# RL6955_IP_SVD register map
Vendor: Realtek
Registers are 32-bit, read-write, reset 0x0 unless marked. A register's access mark holds for its fields unless they carry their own. Offsets are from the block's base; [hi:lo] are bit positions; {n}, {i} and the like mark numbered series.

## WLON
Base 0x40000000
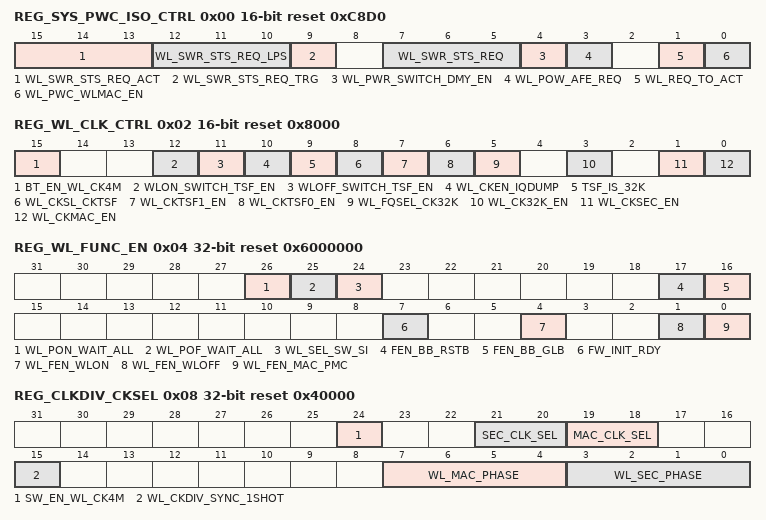
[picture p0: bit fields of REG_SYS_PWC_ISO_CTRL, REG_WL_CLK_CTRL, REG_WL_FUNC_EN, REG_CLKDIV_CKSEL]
0x00 REG_SYS_PWC_ISO_CTRL 16-bit access per field reset 0xC8D0
  [15:13] WL_SWR_STS_REQ_ACT rw — 000: RSVD 001: state1 0.7/PC/PFM 010: state2 0.8/PC/PFM 011: state3 0.9/PC/PFM 100: state4 0.9/SLP/PFM 101: state5 0.9/SLP/PWM 110: state6 0.9/NORM/PWM 111: state7 1.0/NORM/PWM
  [12:10] WL_SWR_STS_REQ_LPS rw — 000: RSVD 001: state1 0.7/PC/PFM 010: state2 0.8/PC/PFM 011: state3 0.9/PC/PFM 100: state4 0.9/SLP/PFM 101: state5 0.9/SLP/PWM 110: state6 0.9/NORM/PWM 111: state7 1.0/NORM/PWM
  [9] WL_SWR_STS_REQ_TRG rw — 1:wl request switch regu status to active mode,which means selectl 0x00[11:9] as request 0:wl request switch regu status to lps mode,which means selectl 0x00[7:5] as request
  [7:5] WL_SWR_STS_REQ ro — the SWR request mode of wifi
  [4] WL_PWR_SWITCH_DMY_EN rw — 1:enable wl dummy load when wlan is switching power mode 0:disable wl dummy load when wlan is switching power mode
  [3] WL_POW_AFE_REQ rw — AFE power on request to afe_ctrl 1:request to turn on AFE pwr 0:turn off AFE pwr
  [1] WL_REQ_TO_ACT rw — notify system to act
  [0] WL_PWC_WLMAC_EN rw — 1: Enable WLOFF power cut
0x02 REG_WL_CLK_CTRL 16-bit access per field reset 0x8000
  [15] BT_EN_WL_CK4M rw — enable WL OSC 4M when bt is active
  [12] WLON_SWITCH_TSF_EN rw — enable wlpmc switch TSF clock to MAC clock
  [11] WLOFF_SWITCH_TSF_EN rw — enable wlpmc switch TSF clock to 32K clock
  [10] WL_CKEN_IQDUMP rw — 0: disable clock for iqdump (LA MODE) 1: enable clock for iqdump (LA MODE) same clock source as security clock
  [9] TSF_IS_32K ro — WL TSF clock status: 0: MAC clock 1: 32K clock
  [8] WL_CKSL_CKTSF rw — 1: TSF clock switch to 32.768KHz; 0: TSF clock switch to MAC clock
  [7] WL_CKTSF1_EN rw — 1: enable port2 tsf clock; 0: gated
  [6] WL_CKTSF0_EN rw — 1: enable port1 tsf clock; 0: gated
  [5] WL_FQSEL_CK32K rw — 1:32K frequency select 32.768KHz 0:32K frequency select 32KHz
  [3] WL_CK32K_EN rw — 1: enable 32k clock; 0: gated
  [1] WL_CKSEC_EN rw — 1: enable MAC security engine clock; 0: gated
  [0] WL_CKMAC_EN rw — 1: enable MAC clock; 0: gated
0x04 REG_WL_FUNC_EN reset 0x6000000
  [26] WL_PON_WAIT_ALL — 1:wait rdy for swr and xtal and pwc in the same state when power on to save time and power
  [25] WL_POF_WAIT_ALL — 1:wait rdy for swr and xtal in the same state when power off to save time and power
  [24] WL_SEL_SW_SI — indicate SW use indirect path to access WLRFC register
  [17] FEN_BB_RSTB — When this bit is set to 0, CCK and OFDM are disabled, and clock are gated. Otherwise, CCK and OFDM are enabled.
  [16] FEN_BB_GLB — When this bit is set to 0 whole BB is reset. When this bit is set, BB is enabled.
  [7] FW_INIT_RDY — CPU fw initialize ready, set by CPU(txrpt info update,used in ptcl)
  [4] WL_FEN_WLON — 1: enable WL partial ON; 0: reset
  [1] WL_FEN_WLOFF — 1: enable WLOFF; 0: reset
  [0] WL_FEN_MAC_PMC — 1: enable MAC PMC; 0: reset
0x08 REG_CLKDIV_CKSEL reset 0x40000
  [24] SW_EN_WL_CK4M — enable WL OSC 4M when cpu want to access wlon reg and wlpmc buffer
  [21:20] SEC_CLK_SEL — 11/10:40M 01:80M 00:160M
  [19:18] MAC_CLK_SEL — 11/10:20M 01:40M 00:80M
  [15] WL_CKDIV_SYNC_1SHOT — 1: sync 40M/80M clock phase with PLL
  [7:4] WL_MAC_PHASE — 40M MAC clock phase control
  [3:0] WL_SEC_PHASE — 80M security clock phase control
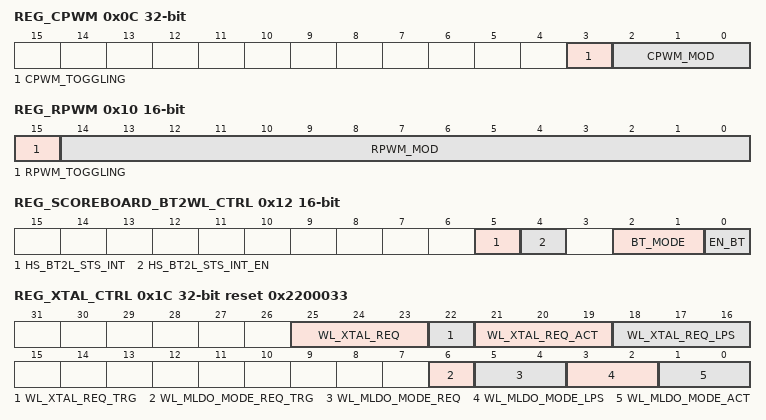
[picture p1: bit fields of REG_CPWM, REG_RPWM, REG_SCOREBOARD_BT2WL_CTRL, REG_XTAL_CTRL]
0x0C REG_CPWM
  [3] CPWM_TOGGLING — Toggling bit : one bit sequence number bit. When this bit is toggled, interrupt is send to HISR.CPWMINT.
  [2:0] CPWM_MOD — The current power mode index.
0x10 REG_RPWM 16-bit
  [15] RPWM_TOGGLING — Toggling bit : one bit sequence number bit. When this bit is toggled, interrupt is send to FISR.RPWMINT.
  [14:0] RPWM_MOD — The current power mode index.
0x12 REG_SCOREBOARD_BT2WL_CTRL 16-bit access per field
  [5] HS_BT2L_STS_INT ro — when bit31 toggles, this interrupt will be assert
  [4] HS_BT2L_STS_INT_EN rw — when bit31 toggles, this interrupt will be assert
  [2:1] BT_MODE rw — Bluetooth Mode
  [0] EN_BT rw — Enable PTA ( from BT side)
0x14 REG_SCOREBOARD_BT2WL ro
  [31:0] RD_BT2WL_INFO — Read Data : WL TO BT INFO, WLON Status Report
0x18 REG_SCOREBOARD_WL2BT
  [31:0] RD_WL2BT_INFO — WLON Status Report TO BTON
0x1C REG_XTAL_CTRL access per field reset 0x2200033
  [25:23] WL_XTAL_REQ ro — the xtal request mode of wifi
  [22] WL_XTAL_REQ_TRG rw — 1: wl request xtal status to active mode,which means selectl 0x30[6:5] as request 0: wl request xtal status to lps mode,which means selectl 0x30[4:3] as request
  [21:19] WL_XTAL_REQ_ACT rw — 000:xtal off 001:xtal lps mode gating 40M 010:xtal lps mode enable 40M 011:xtal normal mode 100:xtal hp mode
  [18:16] WL_XTAL_REQ_LPS rw — 000:xtal off 001:xtal lps mode gating 40M 010:xtal lps mode enable 40M 011:xtal normal mode 100:xtal hp mode
  [6] WL_MLDO_MODE_REQ_TRG rw — Write 1 to trigger switch LDO mode when wifi is active, pulse
  [5:4] WL_MLDO_MODE_REQ ro — The ldo request mode of wifi
  [3:2] WL_MLDO_MODE_LPS rw — 00: analog LDO off 01: analog LDO off sleep 10: analog LDO normal -- dummy load 11: analog LDO normal -- no dummy load
  [1:0] WL_MLDO_MODE_ACT rw — 00: analog LDO off 01: analog LDO off sleep 10: analog LDO normal -- dummy load 11: analog LDO normal -- no dummy load
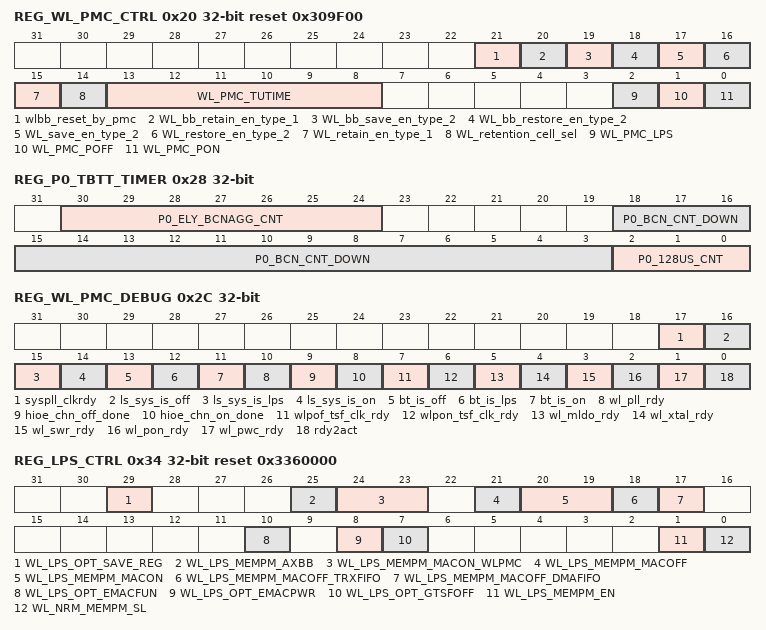
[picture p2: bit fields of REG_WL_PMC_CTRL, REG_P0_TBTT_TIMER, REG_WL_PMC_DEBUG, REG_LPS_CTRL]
0x20 REG_WL_PMC_CTRL access per field reset 0x309F00
  [21] wlbb_reset_by_pmc rw — 1: release wlbb glb reset and restore wlbb retention dff by wlpmc 0:release wlbb glb reset and restore wlbb retention dff by sw or hioe
  [20] WL_bb_retain_en_type_1 rw — 1 to 0:gen req to restore register in power on flow 0 to 1:gen req to backup register in power on flow default should be 1,otherwise there be unexpected leakage power when VCC is power off and VCCG is still on
  [19] WL_bb_save_en_type_2 wo — enable saving value of retention DFF when wlbb power off or pg,should be assert when reset is high
  [18] WL_bb_restore_en_type_2 wo — enable restoring value of retention DFF when wlbb power on,should be assert when reset is high
  [17] WL_save_en_type_2 wo — enable saving value of retention DFF when wlmac power off or pg,should be assert when reset is high
  [16] WL_restore_en_type_2 wo — enable restoring value of retention DFF when wlmac power on,should be assert when reset is high
  [15] WL_retain_en_type_1 rw — 1 to 0:gen req to restore register in power on flow 0 to 1:gen req to backup register in power on flow default should be 1,otherwise there be unexpected leakage power when VCC is power off and VCCG is still on
  [14] WL_retention_cell_sel rw — 1:choose retention cell type I(U22 ULP),which is controlled by 0x20[15] 0:choose retention cell type II(RTKM),which is controlled by 0x20[17:16]
  [13:8] WL_PMC_TUTIME rw — WL PMC FSM counting unit.
  [2] WL_PMC_LPS rw — Inform WLAN PMC FSM to enter LPS mode. (auto clear when ready)
  [1] WL_PMC_POFF rw — Inform WLAN PMC FSM to power OFF mode, include clock, isolation, power control for MAC only (clear when Power Ready)
  [0] WL_PMC_PON rw — Inform WLAN PMC FSM to power On mode, include clock, isolation, power control for MAC only (clear when Power Ready)
0x24 REG_WL_PIN_FUNC_CTRL
  [31:24] WL_DBG_SEL — WL debug select
0x28 REG_P0_TBTT_TIMER ro
  [30:24] P0_ELY_BCNAGG_CNT — Unit: bcn_space the total time to next specified TBTT is (new_ely_agg_cnt - 1) * r_bcn_space(0x554) + (beacon_cnt_down - 1)* 1ms + (cnt_128us + 1)* 128us
  [18:3] P0_BCN_CNT_DOWN — Unit: 1ms beacon_cnt_down - 1
  [2:0] P0_128US_CNT — Unit: 128us
0x2C REG_WL_PMC_DEBUG ro
  [17] syspll_clkrdy, [16] ls_sys_is_off, [15] ls_sys_is_lps, [14] ls_sys_is_on, [13] bt_is_off, [12] bt_is_lps, [11] bt_is_on, [10] wl_pll_rdy, [9] hioe_chn_off_done, [8] hioe_chn_on_done, [7] wlpof_tsf_clk_rdy, [6] wlpon_tsf_clk_rdy, [5] wl_mldo_rdy, [4] wl_xtal_rdy, [3] wl_swr_rdy, [2] wl_pon_rdy, [1] wl_pwc_rdy, [0] rdy2act
0x30 REG_DBG_PORT_REG ro
  [31:0] DEBUG_ST — Debug signals, sel by 24[31:24]
0x34 REG_LPS_CTRL access per field reset 0x3360000
  [29] WL_LPS_OPT_SAVE_REG rw — LPS option to save retention FF 1: enable request to save retention FF 0: disable request to save retention FF
  [25] WL_LPS_MEMPM_AXBB rw — AXBB FTC/SNPS memory power mode when enable LPS memory power mode 0 : normal 1 : NAP/LS
  [24:23] WL_LPS_MEMPM_MACON_WLPMC rw — MAC ON FTC memory power mode when enable LPS memory power mode(for WLPMC BUFFER) 00 : normal 01 : NAP 10 : RET 11 : SLP
  [21] WL_LPS_MEMPM_MACOFF rw — MAC OFF FTC memory power mode when enable LPS memory power mode (for RXPKTBUF/LLT/CISBUF/SR_TABLE) 0 : normal 1 : NAP/LS
  [20:19] WL_LPS_MEMPM_MACON rw — MAC ON FTC memory power mode when enable LPS memory power mode (for EXT_RXPKTBUF/HIOE 4k) 00 : normal 01 : NAP 10 : RET 11 : SLP
  [18] WL_LPS_MEMPM_MACOFF_TRXFIFO rw — MAC OFF FTC/SNPS memory power mode when enable LPS memory power mode (for rxfifo/txfifo) 0 : normal 1 : NAP/LS
  [17] WL_LPS_MEMPM_MACOFF_DMAFIFO rw — MAC OFF SNPS memory power mode when enable LPS memory power mode(dmafifo) 0 : normal 1 : NAP
  [10] WL_LPS_OPT_EMACFUN rw — LPS option to reset WL MAC OFF block when enable WL MAC OFF power 1: not reset WL MAC OFF block 0: reset WL MAC OFF block
  [8] WL_LPS_OPT_EMACPWR rw — LPS option to enable WL MAC OFF block power 1: Enable WL MAC OFF block power 0: Disable WL MAC OFF block power
  [7] WL_LPS_OPT_GTSFOFF rw — LPS option to enable TSF CLK in OFF domain 1: Enable tsf clk gating when lps cg 0: Disable tsf clk gating when lps cg
  [1] WL_LPS_MEMPM_EN rw — enable LPS memory power mode control
  [0] WL_NRM_MEMPM_SL rw — MAC memory power mode when BIT_WL_LPS_MEMPM_EN is 0, 0 : Normal 1 : SD
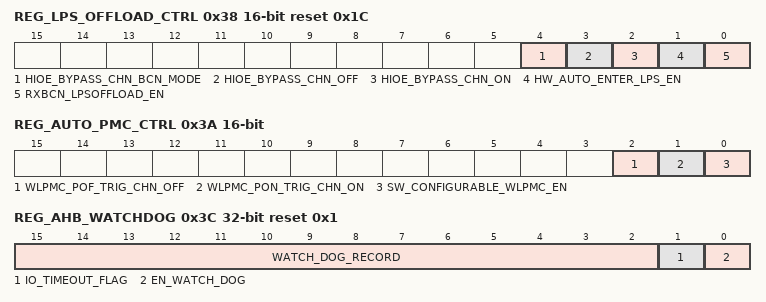
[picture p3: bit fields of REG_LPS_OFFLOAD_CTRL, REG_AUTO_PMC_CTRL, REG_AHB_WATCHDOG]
0x38 REG_LPS_OFFLOAD_CTRL 16-bit reset 0x1C
  [4] HIOE_BYPASS_CHN_BCN_MODE — BYPASS HW trig hioe to do switch bcn mode to normal rx(enable ofdm) flow
  [3] HIOE_BYPASS_CHN_OFF — BYPASS HW trig hioe to do rf off flow
  [2] HIOE_BYPASS_CHN_ON — BYPASS HW trig hioe to do rf on flow
  [1] HW_AUTO_ENTER_LPS_EN — enable HW enter lps after hioe_off_int rise when BIT_FS_RXBCN_LPS_EN=1
  [0] RXBCN_LPSOFFLOAD_EN — enable lps offload flow when rxbcn frame in port0 acting as a non-AP STA.
0x3A REG_AUTO_PMC_CTRL 16-bit
  [2] WLPMC_POF_TRIG_CHN_OFF — ONE pluse to trig hioe_chn_off
  [1] WLPMC_PON_TRIG_CHN_ON — ONE pluse to trig hioe_chn_on, and start rxbcn_timer
  [0] SW_CONFIGURABLE_WLPMC_EN — enable programable wlpmc flow
0x3C REG_AHB_WATCHDOG access per field reset 0x1
  [15:2] WATCH_DOG_RECORD ro — timeout register address
  [1] IO_TIMEOUT_FLAG ro — AHB timeout flag
  [0] EN_WATCH_DOG rw — enable AHB timeout watchdog
0x40 REG_DUMMY_PAGE0
  [7:0] dummy
{0x4C+4i} REG_FW_DBG_PON_{i} (i=1..8)
  [31:0] FW_DBG_PON_{i}
{0x60+4i} REG_FW_DBG_PON_{i} (i=9..11)
  [31:0] FW_DBG_PON_{i}
0x94 REG_FW_DBG_PON_12
  [31:0] FW_DBG_PON_12
0xA0 REG_SW_WLPMC_DEBUG ro
  [31:0] SW_WLPMC_DBG
0xA4 REG_HW_WLPMC_DEBUG ro
  [31:0] HW_WLPMC_DBG
